# STM32WBA64xx register map
File version: 1.0
Registers are 32-bit, read-write, reset 0x0 unless marked. A register's access mark holds for its fields unless they carry their own. Offsets are from the block's base; [hi:lo] are bit positions; {n}, {i} and the like mark numbered series; 'fields as' and 'values as' point back to an identical list.

## RAMCFG
Base 0x40026000
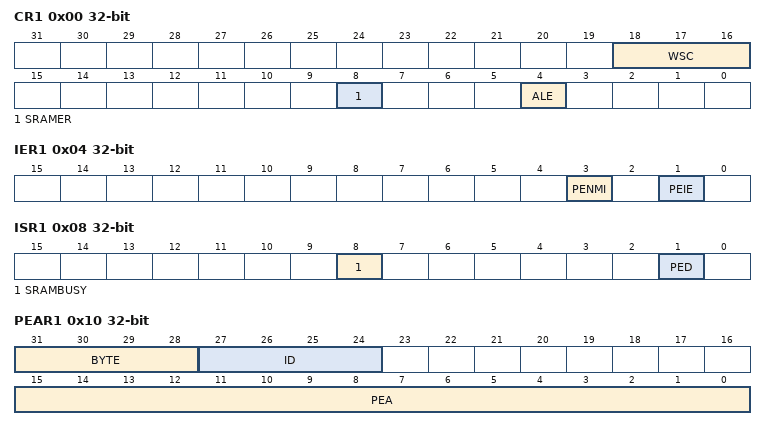
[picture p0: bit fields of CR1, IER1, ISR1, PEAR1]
0x00 CR1 — Control Register
  [18:16] WSC — WSC[18:16] Wait State Configuration field
  [8] SRAMER — Start Erase
  [4] ALE — Address Latching Enable
0x04 IER1 — Interrupt enable register
  [3] PENMI — Parity error NMI
  [1] PEIE — Parity error interrupt enable
0x08 ISR1 — Interrupt status register
  [8] SRAMBUSY — SRAM busy with erase operation
  [1] PED — Parity error detected
0x10 PEAR1 — Parity error address register
  [31:28] BYTE — Byte parity error flag
  [27:24] ID — Parity error AHB bus master ID
  [15:0] PEA — Parity error SRAM word aligned address offset
0x14 ICR1 — Interrupt clear register
  [1] CPED — Clear parity error detect bit
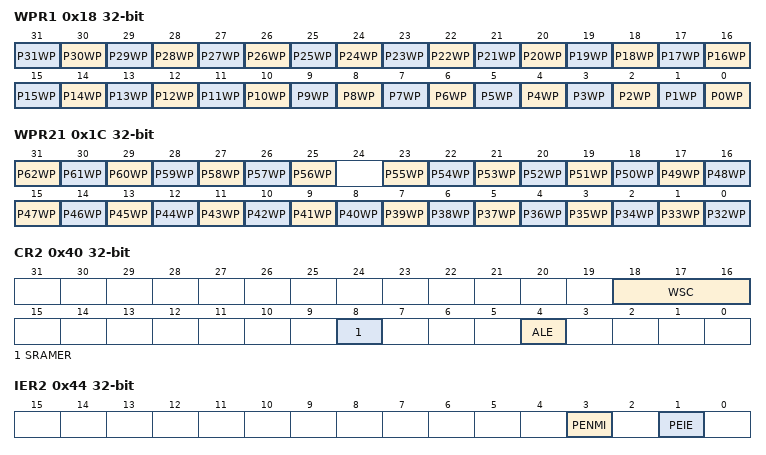
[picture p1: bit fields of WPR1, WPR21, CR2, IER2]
0x18 WPR1 — Write protection register 1
  [n] P{n}WP (n=0..31) — Write Protection Page {n:02}
0x1C WPR21 — Write protection register 2
  [n-31] P{n}WP (n=56..62) — Write Protection Page {n}
  [n-32] P{n}WP (n=32..55) — Write Protection Page {n}
0x28 ERKEYR1 — Erase key register
  [7:0] ERASEKEY — Erase write protection key
0x40 CR2 — Control Register
  fields as CR1
0x44 IER2 — Interrupt enable register
  fields as IER1
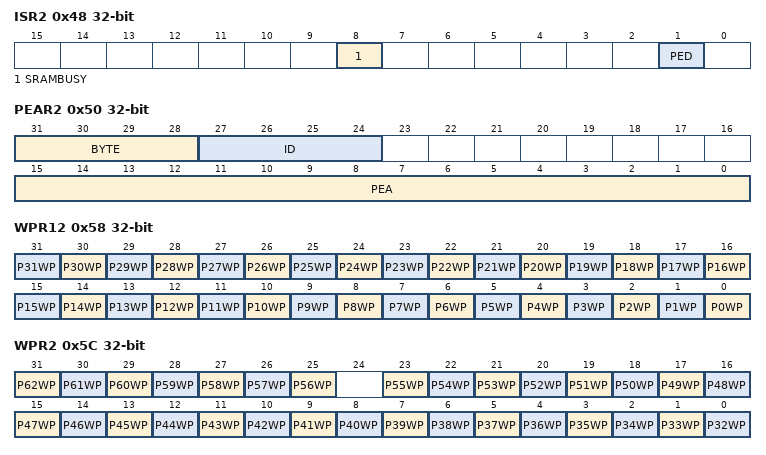
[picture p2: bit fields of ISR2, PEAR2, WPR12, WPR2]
0x48 ISR2 — Interrupt status register
  fields as ISR1
0x50 PEAR2 — Parity error address register
  fields as PEAR1
0x54 ICR2 — Interrupt clear register
  [1] CPED — Clear parity error detect bit
0x58 WPR12 — Write protection register 1
  [n] P{n}WP (n=0..31) — Write Protection Page {n:02}
0x5C WPR2 — Write protection register 2
  fields as WPR21
0x68 ERKEYR2 — Erase key register
  [7:0] ERASEKEY — Erase write protection key
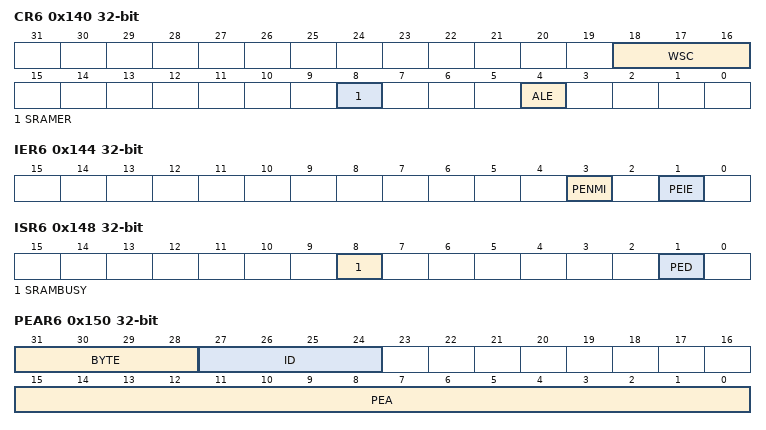
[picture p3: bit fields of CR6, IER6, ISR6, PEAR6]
0x140 CR6 — Control Register
  fields as CR1
0x144 IER6 — Interrupt enable register
  fields as IER1
0x148 ISR6 — Interrupt status register
  fields as ISR1
0x150 PEAR6 — Parity error address register
  fields as PEAR1
0x154 ICR6 — Interrupt clear register
  [1] CPED — Clear parity error detect bit
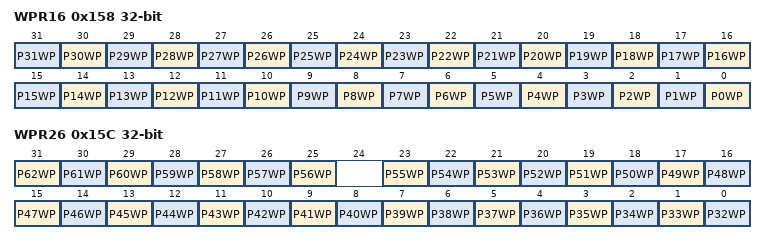
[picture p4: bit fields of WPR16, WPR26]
0x158 WPR16 — Write protection register 1
  [n] P{n}WP (n=0..31) — Write Protection Page {n:02}
0x15C WPR26 — Write protection register 2
  fields as WPR21
0x168 ERKEYR6 — Erase key register
  [7:0] ERASEKEY — Erase write protection key

## ICACHE — Instruction Cache
Base 0x40030400
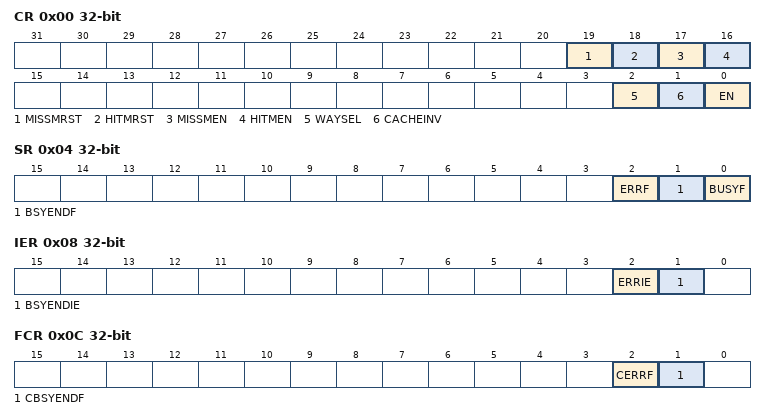
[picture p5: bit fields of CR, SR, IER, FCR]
0x00 CR — ICACHE control register
  [19] MISSMRST — Miss monitor reset
  [18] HITMRST — Hit monitor reset
  [17] MISSMEN — Miss monitor enable
  [16] HITMEN — Hit monitor enable
  [2] WAYSEL — Ways selection
    0=ICACHE_1WAY (1-way cache (direct mapped cache)); 1=ICACHE_2WAYS (2-ways set associative cache (default))
  [1] CACHEINV — Cache invalidation
  [0] EN — Enable
0x04 SR — ICACHE status register
  [2] ERRF — Cache error flag
  [1] BSYENDF — Busy end flag
  [0] BUSYF — Busy flag
0x08 IER — ICACHE interrupt enable register
  [2] ERRIE — Cache error interrupt enable
  [1] BSYENDIE — Busy end interrupt enable
0x0C FCR — ICACHE Flag clear register
  [2] CERRF — Cache error flag clear
  [1] CBSYENDF — Busy end flag clear
0x10 HMONR — ICACHE hit monitor register
  [31:0] HITMON — Cache hit monitor register
0x14 MMONR — ICACHE miss monitor register
  [15:0] MISSMON — Cache miss monitor register
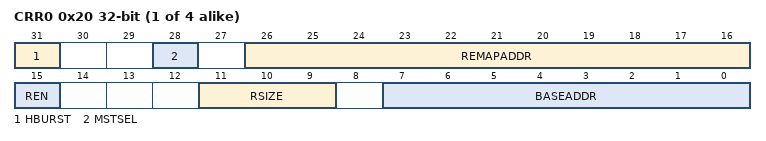
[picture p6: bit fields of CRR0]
{0x20+4i} CRR{i} (i=0..3) — ICACHE region {i} configuration register
  [31] HBURST — Region X output burst type
  [28] MSTSEL — Region X AHB cache master selection
  [26:16] REMAPADDR — Remap address of Region X to be remapped
  [15] REN — Region X enable
  [11:9] RSIZE — Region X size
  [7:0] BASEADDR — Base address of region X to remap

## GTZC_MPCBB1
Base 0x40032C00
Same registers: GTZC_MPCBB2 0x40033000, GTZC_MPCBB6 0x40034000
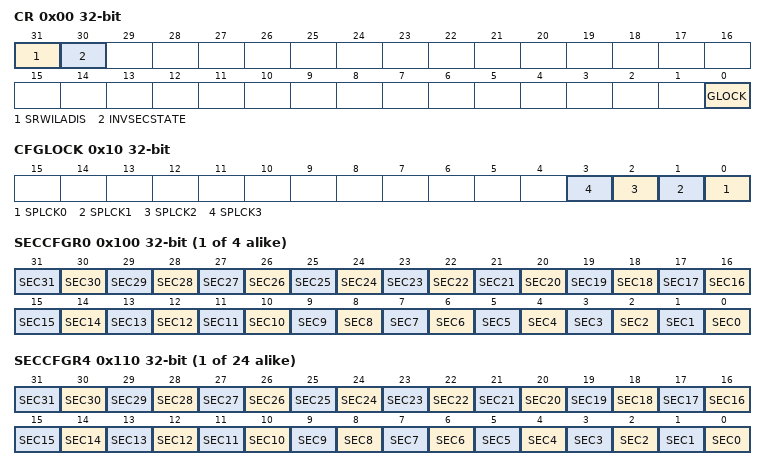
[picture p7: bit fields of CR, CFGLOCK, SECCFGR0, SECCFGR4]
0x00 CR — MPCBBx control register
  [31] SRWILADIS — secure read/write illegal access disable
  [30] INVSECSTATE — SRAM clocks security state
  [0] GLOCK — lock the control register of the MPCBB until next reset
0x10 CFGLOCK — MPCBBx lock register
  [n] SPLCK{n} (n=0..3) — Security/privilege configuration lock super-block {n}
{0x100+4i} SECCFGR{i} (i=0..3) — MPCBBx security configuration registers
  [n] SEC{n} (n=0..31) — Security configuration for block {n} in super block {i}
{0x100+4i} SECCFGR{i} (i=4..27) — MPCBBx security configuration registers
  [n] SEC{n} (n=0..31) — Security configuration for block {n} in super block 0
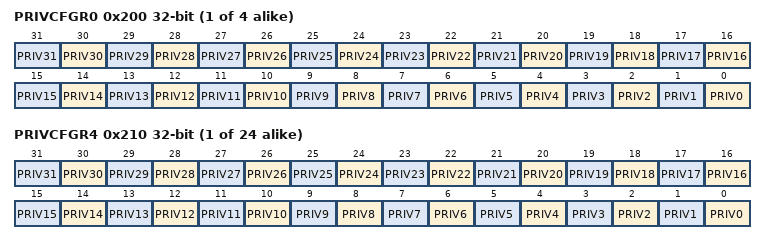
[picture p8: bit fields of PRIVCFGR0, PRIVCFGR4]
{0x200+4i} PRIVCFGR{i} (i=0..3) — MPCBBx privilege configuration registers
  [n] PRIV{n} (n=0..31) — Privileged configuration for block {n} in super block {i}
{0x200+4i} PRIVCFGR{i} (i=4..27) — MPCBBx privilege configuration registers
  [n] PRIV{n} (n=0..31) — Privileged configuration for block {n} in super block 0
